# PIC32CZ2051CA70144 device description
Architecture: CORTEX-M7; Family: PIC32C; Series: PIC32CZCA70
Registers are 32-bit, read-write, no defined reset value unless marked. A register's access mark holds for its fields unless they carry their own. Offsets are from the block's base; [hi:lo] are bit positions; lines under a group give offsets from that group; {n}, {i} and the like mark numbered series; 'fields as' and 'values as' point back to an identical list.

## SCB — System Control Block Registers
Instances: SCB 0xE000ED00
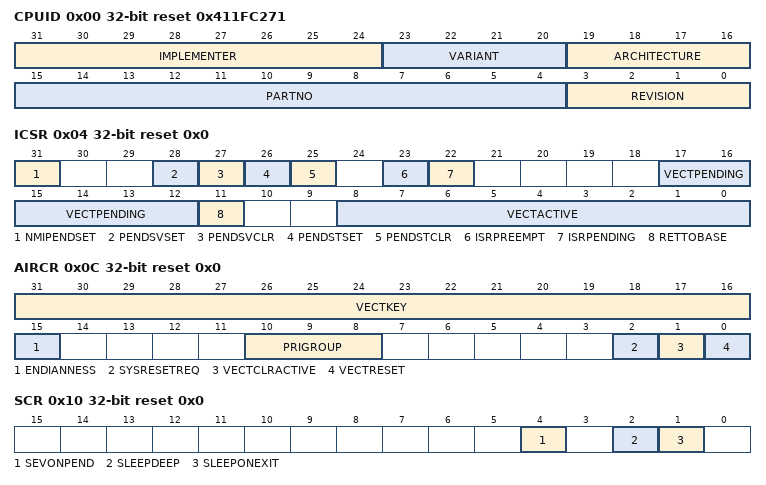
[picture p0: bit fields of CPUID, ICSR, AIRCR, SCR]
0x00 CPUID ro reset 0x411FC271 — CPUID Base Register
  [31:24] IMPLEMENTER — Implementer code
  [23:20] VARIANT — Indicates processor revision: 0x2 = Revision 2
  [19:16] ARCHITECTURE — Indicates architecture. Reads as 0xF
  [15:4] PARTNO — Indicates part number
  [3:0] REVISION — Indicates patch release: 0x0 = Patch 0
0x04 ICSR access not given reset 0x0 — Interrupt Control and State Register
  [31] NMIPENDSET — Makes the NMI exception active, or reads the state of the exception
    0=write: no effect; read: NMI exception is not pending; 1=write: changes NMI exception state to pending; read: NMI exception is pending
  [28] PENDSVSET — Sets the PendSV exception as pending, or reads the current state of the exception
    0=write: no effect; read: PendSV exception is not pending; 1=write: changes PendSV exception state to pending; read: PendSV exception is pending
  [27] PENDSVCLR — Removes the pending status of the PendSV exception
    0=no effect; 1=removes the pending state from the PendSV exception
  [26] PENDSTSET — Sets the SysTick exception as pending, or reads the current state of the exception
    0=write: no effect; read: SysTick exception is not pending; 1=write: changes SysTick exception state to pending; read: SysTick exception is pending
  [25] PENDSTCLR — Removes the pending status of the SysTick exception
    0=no effect; 1=removes the pending state from the SysTick exception
  [23] ISRPREEMPT — Indicates whether a pending exception will be serviced on exit from debug halt state
    0=Will not service; 1=Will service a pending exception
  [22] ISRPENDING — Is external interrupt, generated by the NVIC, pending
  [17:12] VECTPENDING — Exception number of the highest priority pending enabled exception
  [11] RETTOBASE — Indicates whether there is an active exception other than the exception indicated by the current value of the IPSR
    0=there are preempted active exceptions to execute; 1=there are no active exceptions, or the currently-executing exception is the only active exception
  [8:0] VECTACTIVE — Active exception number
0x08 VTOR access not given reset 0x0 — Vector Table Offset Register
  [31:7] TBLOFF — Bits[31:7] of the vector table address
0x0C AIRCR access not given reset 0x0 — Application Interrupt and Reset Control Register
  [31:16] VECTKEY — Vector key
  [15] ENDIANNESS — Memory system endianness
    0=Little-endian; 1=Big-endian
  [10:8] PRIGROUP — Interrupt priority grouping field. This field determines the split of group priority from subpriority.
  [2] SYSRESETREQ — System Reset Request
    0=no system reset request; 1=asserts a signal to the outer system that requests a reset
  [1] VECTCLRACTIVE — Clears all active state information for fixed and configurable exceptions
  [0] VECTRESET — Writing 1 to this bit causes a local system reset
0x10 SCR access not given reset 0x0 — System Control Register
  [4] SEVONPEND — Determines whether an interrupt transition from inactive state to pending state is a wakeup event
    0=only enabled interrupts or events can wakeup the processor, disabled interrupts are excluded; 1=enabled events and all interrupts, including disabled interrupts, can wakeup the processor
  [2] SLEEPDEEP — Provides a qualifying hint indicating that waking from sleep might take longer
    0=sleep; 1=deep sleep
  [1] SLEEPONEXIT — Determines whether, on an exit from an ISR that returns to the base level of execution priority, the processor enters a sleep state
    0=o not sleep when returning to Thread mode; 1=enter sleep, or deep sleep, on return from an ISR
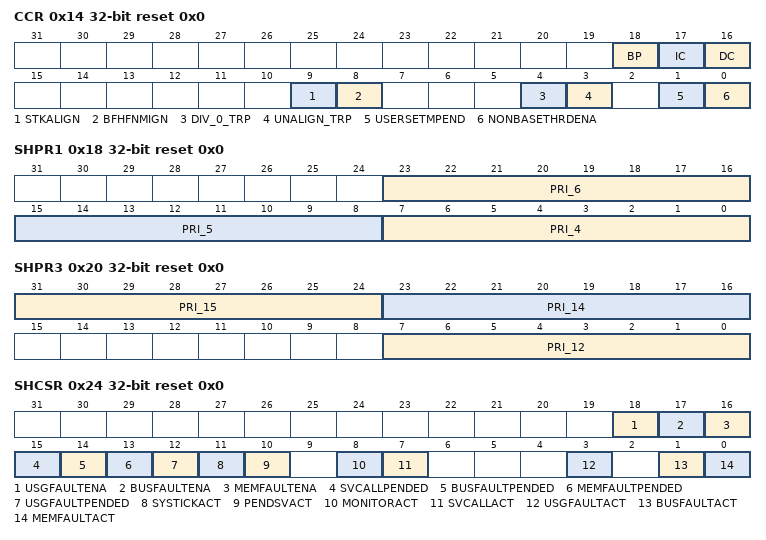
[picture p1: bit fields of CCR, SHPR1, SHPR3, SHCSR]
0x14 CCR access not given reset 0x0 — Configuration and Control Register
  [18] BP — Branch prediction enable bi
  [17] IC — Instruction cache enable bi
  [16] DC — Cache enable bit
  [9] STKALIGN — Indicates stack alignment on exception entry
    0=4-byte aligned; 1=8-byte aligned
  [8] BFHFNMIGN — Enables handlers with priority -1 or -2 to ignore data BusFaults caused by load and store instructions.
    0=data bus faults caused by load and store instructions cause a lock-up; 1=handlers running at priority -1 and -2 ignore data bus faults caused by load and store instructions
  [4] DIV_0_TRP — Enables faulting or halting when the processor executes an SDIV or UDIV instruction with a divisor of 0
    0=do not trap divide by 0; 1=trap divide by 0
  [3] UNALIGN_TRP — Enables unaligned access traps
    0=do not trap unaligned halfword and word accesses; 1=trap unaligned halfword and word accesses
  [1] USERSETMPEND — Enables unprivileged software access to the STIR
    0=disable; 1=enable
  [0] NONBASETHRDENA — Controls whether the processor can enter Thread mode with exceptions active
    0=processor can enter Thread mode only when no exception is active; 1=processor can enter Thread mode from any level under the control of an EXC_RETURN value
0x18 SHPR1 access not given reset 0x0 — System Handler Priority Register 1
  [23:16] PRI_6 — Priority of system handler 6, UsageFault
  [15:8] PRI_5 — Priority of system handler 5, BusFault
  [7:0] PRI_4 — Priority of system handler 4, MemManage
0x1C SHPR2 access not given reset 0x0 — System Handler Priority Register 2
  [31:24] PRI_11 — Priority of system handler 11, SVCall
0x20 SHPR3 access not given reset 0x0 — System Handler Priority Register 3
  [31:24] PRI_15 — Priority of system handler 15, SysTick exception
  [23:16] PRI_14 — Priority of system handler 14, PendSV
  [7:0] PRI_12 — Priority of system handler 12, SysTick
0x24 SHCSR access not given reset 0x0 — System Handler Control and State Register
  [18] USGFAULTENA
    0=disable the exception; 1=enable the exception
  [17] BUSFAULTENA
    0=disable the exception; 1=enable the exception
  [16] MEMFAULTENA
    0=disable the exception; 1=enable the exception
  [15] SVCALLPENDED
    0=exception is not pending; 1=exception is pending
  [14] BUSFAULTPENDED
    0=exception is not pending; 1=exception is pending
  [13] MEMFAULTPENDED
    0=exception is not pending; 1=exception is pending
  [12] USGFAULTPENDED
    0=exception is not pending; 1=exception is pending
  [11] SYSTICKACT
    0=exception is not active; 1=exception is active
  [10] PENDSVACT
    0=exception is not active; 1=exception is active
  [8] MONITORACT
    0=exception is not active; 1=exception is active
  [7] SVCALLACT
    0=exception is not active; 1=exception is active
  [3] USGFAULTACT
    0=exception is not active; 1=exception is active
  [1] BUSFAULTACT
    0=exception is not active; 1=exception is active
  [0] MEMFAULTACT
    0=exception is not active; 1=exception is active
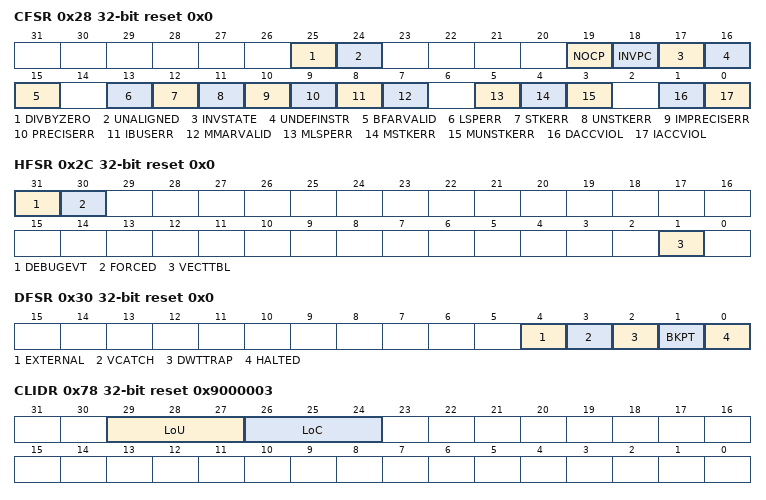
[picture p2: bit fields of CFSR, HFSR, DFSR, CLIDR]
0x28 CFSR access not given reset 0x0 — Configurable Fault Status Registers
  [25] DIVBYZERO
    0=no divide by zero fault, or divide by zero trapping not enabled; 1=the processor has executed an SDIV or UDIV instruction with a divisor of 0
  [24] UNALIGNED
    0=no unaligned access fault, or unaligned access trapping not enabled; 1=the processor has made an unaligned memory access
  [19] NOCP
    0=no UsageFault caused by attempting to access a coprocessor; 1=the processor has attempted to access a coprocessor
  [18] INVPC
    0=no invalid PC load UsageFault; 1=the processor has attempted an illegal load of EXC_RETURN to the PC
  [17] INVSTATE
    0=no invalid state UsageFault; 1=the processor has attempted to execute an instruction that makes illegal use of the EPSR
  [16] UNDEFINSTR
    0=no undefined instruction UsageFault; 1=the processor has attempted to execute an undefined instruction
  [15] BFARVALID
    0=value in BFAR is not a valid fault address; 1=BFAR holds a valid fault address
  [13] LSPERR
    0=No bus fault occurred during floating-point lazy state preservation; 1=A bus fault occurred during floating-point lazy state preservation
  [12] STKERR
    0=no stacking fault; 1=stacking for an exception entry has caused one or more BusFaults
  [11] UNSTKERR
    0=no unstacking fault; 1=unstack for an exception return has caused one or more BusFaults
  [10] IMPRECISERR
    0=no imprecise data bus error; 1=a data bus error has occurred, but the return address in the stack frame is not related to the instruction that caused the error
  [9] PRECISERR
    0=no precise data bus error; 1=a data bus error has occurred, and the PC value stacked for the exception return points to the instruction that caused the fault
  [8] IBUSERR
    0=no instruction bus error; 1=instruction bus error
  [7] MMARVALID
    0=value in MMAR is not a valid fault address; 1=MMAR holds a valid fault address
  [5] MLSPERR
    0=No MemManage fault occurred during floating-point lazy state preservation; 1=A MemManage fault occurred during floating-point lazy state preservation
  [4] MSTKERR
    0=no stacking fault; 1=stacking for an exception entry has caused one or more access violations
  [3] MUNSTKERR
    0=no unstacking fault; 1=unstack for an exception return has caused one or more access violations
  [1] DACCVIOL
    0=no data access violation fault; 1=the processor attempted a load or store at a location that does not permit the operation
  [0] IACCVIOL
    0=no instruction access violation fault; 1=the processor attempted an instruction fetch from a location that does not permit execution
0x2C HFSR access not given reset 0x0 — HardFault Status register
  [31] DEBUGEVT — Indicates when a Debug event has occurred
  [30] FORCED — Indicates that a fault with configurable priority has been escalated to a HardFault exception
    0=no forced HardFault; 1=forced HardFault
  [1] VECTTBL — Indicates when a fault has occurred because of a vector table read error on exception processing
    0=no BusFault on vector table read; 1=BusFault on vector table read
0x30 DFSR access not given reset 0x0 — Debug Fault Status Register
  [4] EXTERNAL — debug event generated because of the assertion of an external debug request
    0=No EDBGRQ debug event; 1=EDBGRQ debug event
  [3] VCATCH — triggering of a Vector catch
    0=No Vector catch triggered; 1=Vector catch triggered
  [2] DWTTRAP — debug event generated by the DWT
    0=No current debug events generated by the DWT; 1=At least one current debug event generated by the DWT
  [1] BKPT — debug event generated by BKPT instruction execution or a breakpoint match in FPB
    0=No current breakpoint debug event; 1=At least one current breakpoint debug event
  [0] HALTED — debug event generated by
    0=No active halt request debug event; 1=Halt request debug event active
0x34 MMFAR access not given reset 0x0 — MemManage Fault Address Register
  [31:0] ADDRESS — Data address for an MPU fault
0x38 BFAR access not given reset 0x0 — BusFault Address Register
  [31:0] ADDRESS — Data address for a precise bus fault
0x3C AFSR access not given reset 0x0 — Auxiliary Fault Status Register
0x78 CLIDR ro reset 0x9000003 — Cache Level ID Register
  [29:27] LoU — Level of Unification
    0=LEVEL_1 (if neither instruction nor data cache is implemented); 1=LEVEL_2 (if either cache is implemented)
  [26:24] LoC — Level of Coherency
    values as LoU
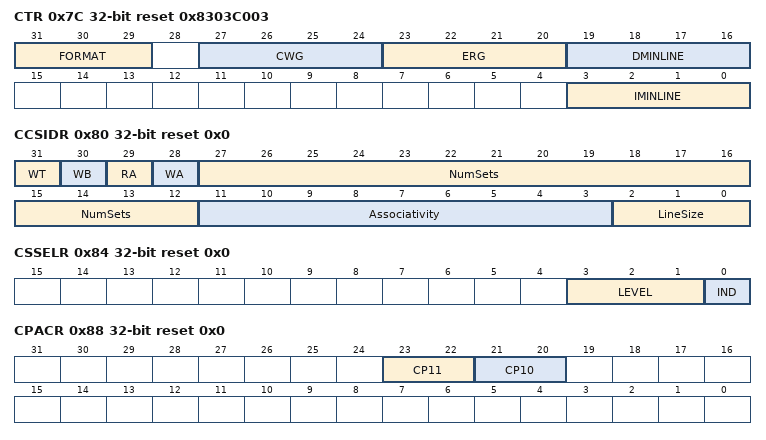
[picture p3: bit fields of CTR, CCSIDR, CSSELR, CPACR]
0x7C CTR ro reset 0x8303C003 — Cache Type Register
  [31:29] FORMAT
  [27:24] CWG — Cache Writeback Granule
  [23:20] ERG — Exclusives Reservation Granule
  [19:16] DMINLINE — Smallest cache line of all the data and unified caches under the core control
  [3:0] IMINLINE — Smallest cache line of all the instruction caches under the control of the processor
0x80 CCSIDR ro reset 0x0 — Cache Size ID Register
  [31] WT — Write-Through support
  [30] WB — Write-Back support
  [29] RA — Read allocation support
  [28] WA — Write allocation support
  [27:12] NumSets — number of sets
  [11:3] Associativity — number of ways
  [2:0] LineSize — number of words in each cache line
0x84 CSSELR access not given reset 0x0 — Cache Size Selection Register
  [3:1] LEVEL — cache level selected
  [0] IND — selection of instruction or data cache
    0=DATA (Data cache); 1=INSTRUCTION (Instruction cache)
0x88 CPACR access not given reset 0x0 — Coprocessor Access Control Register
  [23:22] CP11 — Access privileges for coprocessor 11.
  [21:20] CP10 — Access privileges for coprocessor 10.
0x150 ICIALLU wo — I-cache invalidate all to PoU
0x158 ICIMVAU wo — I-cache invalidate by MVA to PoU
0x15C DCIMVAC wo — D-cache invalidate by MVA to PoC
0x160 DCISW wo — D-cache invalidate by set-way
0x164 DCCMVAU wo — D-cache clean by MVA to PoU
0x168 DCCMVAC wo — D-cache clean by MVA to PoC
0x16C DCCSW wo — D-cache clean by set-way
0x170 DCCIMVAC wo — D-cache clean and invalidate by MVA to PoC
0x174 DCCISW wo — D-cache clean and invalidate by set-way
0x178 BPIALL wo — Branch predictor invalidate all
0x200 STIR wo reset 0x0 — Software Trigger Interrupt Register
  [8:0] INTID — Interrupt ID of the interrupt to trigger, in the range 0-239. For example, a value of 0x03 specifies interrupt IRQ3.
{0x240+4i} MVFR{i} ro reset 0x10110021 (i=0..2) — Media and VFP Feature Register {i}
